# MK30D7 register map
File version: 1.6
Registers are 32-bit, read-write, reset 0x0 unless marked. A register's access mark holds for its fields unless they carry their own. Offsets are from the block's base; [hi:lo] are bit positions; {n}, {i} and the like mark numbered series; 'fields as' and 'values as' point back to an identical list.

## FMC — Flash Memory Controller
Base 0x4001F000; register names take the prefix FMC_
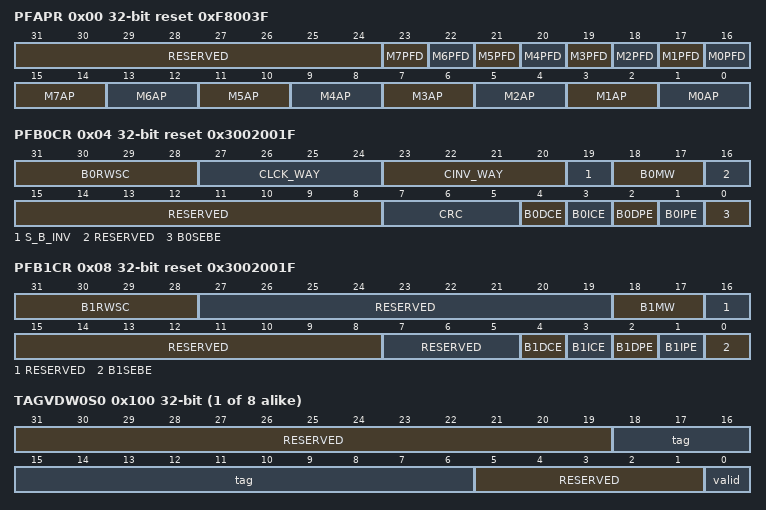
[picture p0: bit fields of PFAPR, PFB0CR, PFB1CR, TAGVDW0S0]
0x00 PFAPR access per field reset 0xF8003F — Flash Access Protection Register
  [31:24] RESERVED ro
  [n+16] M{n}PFD rw (n=0..7) — Master {n} Prefetch Disable
    0=Prefetching for this master is enabled; 1=Prefetching for this master is disabled
  [2n+1:2n] M{n}AP rw (n=0..7) — Master {n} Access Protection
    0=No access may be performed by this master; 1=Only read accesses may be performed by this master; 2=Only write accesses may be performed by this master; 3=Both read and write accesses may be performed by this master
0x04 PFB0CR access per field reset 0x3002001F — Flash Bank 0 Control Register
  [31:28] B0RWSC ro — Bank 0 Read Wait State Control
  [27:24] CLCK_WAY rw — Cache Lock Way x
    0=Cache way is unlocked and may be displaced; 1=Cache way is locked and its contents are not displaced
  [23:20] CINV_WAY wo — Cache Invalidate Way x
    0=No cache way invalidation for the corresponding cache; 1=Invalidate cache way for the corresponding cache: clear the tag, data, and vld bits of ways selected
  [19] S_B_INV wo — Invalidate Prefetch Speculation Buffer
    0=Speculation buffer and single entry buffer are not affected; 1=Invalidate (clear) speculation buffer and single entry buffer
  [18:17] B0MW ro — Bank 0 Memory Width
    0=32 bits; 1=64 bits
  [16] RESERVED ro
  [15:8] RESERVED ro
  [7:5] CRC rw — Cache Replacement Control
    0=LRU replacement algorithm per set across all four ways; 2=Independent LRU with ways [0-1] for ifetches, [2-3] for data; 3=Independent LRU with ways [0-2] for ifetches, [3] for data
  [4] B0DCE rw — Bank 0 Data Cache Enable
    0=Do not cache data references; 1=Cache data references
  [3] B0ICE rw — Bank 0 Instruction Cache Enable
    0=Do not cache instruction fetches; 1=Cache instruction fetches
  [2] B0DPE rw — Bank 0 Data Prefetch Enable
    0=Do not prefetch in response to data references; 1=Enable prefetches in response to data references
  [1] B0IPE rw — Bank 0 Instruction Prefetch Enable
    0=Do not prefetch in response to instruction fetches; 1=Enable prefetches in response to instruction fetches
  [0] B0SEBE rw — Bank 0 Single Entry Buffer Enable
    0=Single entry buffer is disabled; 1=Single entry buffer is enabled
0x08 PFB1CR access per field reset 0x3002001F — Flash Bank 1 Control Register
  [31:28] B1RWSC ro — Bank 1 Read Wait State Control
  [27:19] RESERVED ro
  [18:17] B1MW ro — Bank 1 Memory Width
    0=32 bits; 1=64 bits
  [16] RESERVED ro
  [15:8] RESERVED ro
  [7:5] RESERVED ro
  [4] B1DCE rw — Bank 1 Data Cache Enable
    0=Do not cache data references; 1=Cache data references
  [3] B1ICE rw — Bank 1 Instruction Cache Enable
    values as PFB0CR.B0ICE
  [2] B1DPE rw — Bank 1 Data Prefetch Enable
    values as PFB0CR.B0DPE
  [1] B1IPE rw — Bank 1 Instruction Prefetch Enable
    values as PFB0CR.B0IPE
  [0] B1SEBE rw — Bank 1 Single Entry Buffer Enable
    values as PFB0CR.B0SEBE
{0x100+4i} TAGVDW0S{i} (i=0..7) access per field — Cache Tag Storage
  [31:19] RESERVED ro
  [18:6] tag rw — 13-bit tag for cache entry
  [5:1] RESERVED ro
  [0] valid rw — 1-bit valid for cache entry
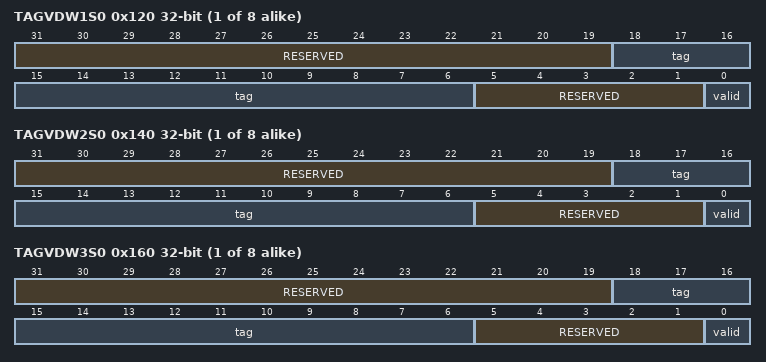
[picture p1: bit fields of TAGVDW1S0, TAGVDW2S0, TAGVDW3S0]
{0x120+4i} TAGVDW1S{i} (i=0..7) access per field — Cache Tag Storage
  fields as TAGVDW0S0
{0x140+4i} TAGVDW2S{i} (i=0..7) access per field — Cache Tag Storage
  fields as TAGVDW0S0
{0x160+4i} TAGVDW3S{i} (i=0..7) access per field — Cache Tag Storage
  fields as TAGVDW0S0
{0x200+8i} DATAW0S{i}U (i=0..7) — Cache Data Storage (upper word)
  [31:0] data — Bits [63:32] of data entry
{0x204+8i} DATAW0S{i}L (i=0..7) — Cache Data Storage (lower word)
  [31:0] data — Bits [31:0] of data entry
{0x240+8i} DATAW1S{i}U (i=0..7) — Cache Data Storage (upper word)
  [31:0] data — Bits [63:32] of data entry
{0x244+8i} DATAW1S{i}L (i=0..7) — Cache Data Storage (lower word)
  [31:0] data — Bits [31:0] of data entry
{0x280+8i} DATAW2S{i}U (i=0..7) — Cache Data Storage (upper word)
  [31:0] data — Bits [63:32] of data entry
{0x284+8i} DATAW2S{i}L (i=0..7) — Cache Data Storage (lower word)
  [31:0] data — Bits [31:0] of data entry
{0x2C0+8i} DATAW3S{i}U (i=0..7) — Cache Data Storage (upper word)
  [31:0] data — Bits [63:32] of data entry
{0x2C4+8i} DATAW3S{i}L (i=0..7) — Cache Data Storage (lower word)
  [31:0] data — Bits [31:0] of data entry
